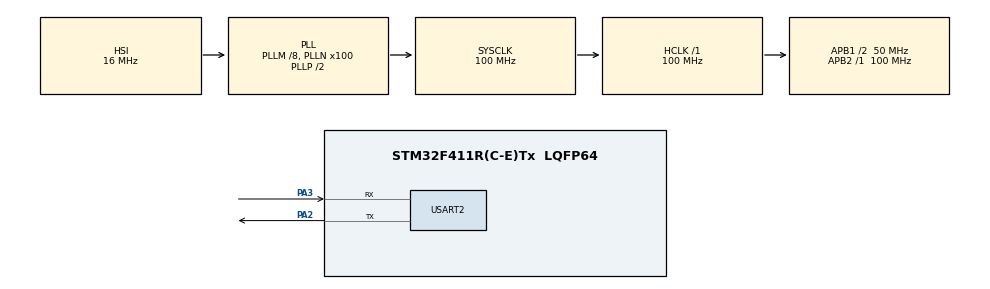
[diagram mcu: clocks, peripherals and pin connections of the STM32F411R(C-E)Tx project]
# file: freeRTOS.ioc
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FREERTOS.Tasks01=defaultTask,24,128,StartDefaultTask,Default,NULL,Dynamic,NULL,NULL;task1,8,128,funcTask1,Default,NULL,Dynamic,NULL,NULL;task2,8,128,funcTask2,Default,NULL,Dynamic,NULL,NULL
Mcu.Family=STM32F4
Mcu.Name=STM32F411R(C-E)Tx
Mcu.Package=LQFP64
NVIC.PriorityGroup=NVIC_PRIORITYGROUP_4
PA2.Mode=Asynchronous
PA2.Signal=USART2_TX
PA3.Mode=Asynchronous
PA3.Signal=USART2_RX
ProjectManager.HeapSize=0x200
ProjectManager.StackSize=0x400
ProjectManager.TargetToolchain=STM32CubeIDE
RCC.48MHZClocksFreq_Value=50000000
RCC.AHBFreq_Value=100000000
RCC.APB1CLKDivider=RCC_HCLK_DIV2
RCC.APB1Freq_Value=50000000
RCC.APB1TimFreq_Value=100000000
RCC.APB2Freq_Value=100000000
RCC.APB2TimFreq_Value=100000000
RCC.CortexFreq_Value=100000000
RCC.HCLKFreq_Value=100000000
RCC.HSE_VALUE=25000000
RCC.HSI_VALUE=16000000
RCC.LSE_VALUE=32768
RCC.PLLM=8
RCC.PLLN=100
RCC.SYSCLKFreq_VALUE=100000000
RCC.SYSCLKSource=RCC_SYSCLKSOURCE_PLLCLK
RCC.VCOOutputFreq_Value=200000000
USART2.VirtualMode=VM_ASYNC
VP_FREERTOS_VS_CMSIS_V2.Mode=CMSIS_V2
board=custom

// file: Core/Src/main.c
/* USER CODE BEGIN Header */
/**
  ******************************************************************************
  * @file           : main.c
  * @brief          : Main program body
  ******************************************************************************
  * @attention
  *
  * Copyright (c) 2024 STMicroelectronics.
  * All rights reserved.
  *
  * This software is licensed under terms that can be found in the LICENSE file
  * in the root directory of this software component.
  * If no LICENSE file comes with this software, it is provided AS-IS.
  *
  ******************************************************************************
  */
/* USER CODE END Header */
#include "main.h"
#include "cmsis_os.h"

UART_HandleTypeDef huart2;

/* Definitions for defaultTask */
osThreadId_t defaultTaskHandle;
const osThreadAttr_t defaultTask_attributes = {
  .name = "defaultTask",
  .stack_size = 128 * 4,
  .priority = (osPriority_t) osPriorityNormal,
};
/* Definitions for task1 */
osThreadId_t task1Handle;
const osThreadAttr_t task1_attributes = {
  .name = "task1",
  .stack_size = 128 * 4,
  .priority = (osPriority_t) osPriorityLow,
};
/* Definitions for task2 */
osThreadId_t task2Handle;
const osThreadAttr_t task2_attributes = {
  .name = "task2",
  .stack_size = 128 * 4,
  .priority = (osPriority_t) osPriorityLow,
};

void SystemClock_Config(void);
static void MX_GPIO_Init(void);
static void MX_USART2_UART_Init(void);
void StartDefaultTask(void *argument);
void funcTask1(void *argument);
void funcTask2(void *argument);

int main(void)
{

  /* MCU Configuration--------------------------------------------------------*/

  /* Reset of all peripherals, Initializes the Flash interface and the Systick. */
  HAL_Init();

  /* Configure the system clock */
  SystemClock_Config();

  /* Initialize all configured peripherals */
  MX_GPIO_Init();
  MX_USART2_UART_Init();

  /* Init scheduler */
  osKernelInitialize();

  /* Create the thread(s) */
  /* creation of defaultTask */
  defaultTaskHandle = osThreadNew(StartDefaultTask, NULL, &defaultTask_attributes);

  /* creation of task1 */
  task1Handle = osThreadNew(funcTask1, NULL, &task1_attributes);

  /* creation of task2 */
  task2Handle = osThreadNew(funcTask2, NULL, &task2_attributes);

  /* Start scheduler */
  osKernelStart();

  /* We should never get here as control is now taken by the scheduler */
  /* Infinite loop */
  while (1)
  {

  }
}

void SystemClock_Config(void)
{
  RCC_OscInitTypeDef RCC_OscInitStruct = {0};
  RCC_ClkInitTypeDef RCC_ClkInitStruct = {0};

  /** Configure the main internal regulator output voltage
  */
  __HAL_RCC_PWR_CLK_ENABLE();
  __HAL_PWR_VOLTAGESCALING_CONFIG(PWR_REGULATOR_VOLTAGE_SCALE1);

  /** Initializes the RCC Oscillators according to the specified parameters
  * in the RCC_OscInitTypeDef structure.
  */
  RCC_OscInitStruct.OscillatorType = RCC_OSCILLATORTYPE_HSI;
  RCC_OscInitStruct.HSIState = RCC_HSI_ON;
  RCC_OscInitStruct.HSICalibrationValue = RCC_HSICALIBRATION_DEFAULT;
  RCC_OscInitStruct.PLL.PLLState = RCC_PLL_ON;
  RCC_OscInitStruct.PLL.PLLSource = RCC_PLLSOURCE_HSI;
  RCC_OscInitStruct.PLL.PLLM = 8;
  RCC_OscInitStruct.PLL.PLLN = 100;
  RCC_OscInitStruct.PLL.PLLP = RCC_PLLP_DIV2;
  RCC_OscInitStruct.PLL.PLLQ = 4;
  if (HAL_RCC_OscConfig(&RCC_OscInitStruct) != HAL_OK)
  {
    Error_Handler();
  }

  /** Initializes the CPU, AHB and APB buses clocks
  */
  RCC_ClkInitStruct.ClockType = RCC_CLOCKTYPE_HCLK|RCC_CLOCKTYPE_SYSCLK
                              |RCC_CLOCKTYPE_PCLK1|RCC_CLOCKTYPE_PCLK2;
  RCC_ClkInitStruct.SYSCLKSource = RCC_SYSCLKSOURCE_PLLCLK;
  RCC_ClkInitStruct.AHBCLKDivider = RCC_SYSCLK_DIV1;
  RCC_ClkInitStruct.APB1CLKDivider = RCC_HCLK_DIV2;
  RCC_ClkInitStruct.APB2CLKDivider = RCC_HCLK_DIV1;

  if (HAL_RCC_ClockConfig(&RCC_ClkInitStruct, FLASH_LATENCY_3) != HAL_OK)
  {
    Error_Handler();
  }
}

static void MX_USART2_UART_Init(void)
{

  huart2.Instance = USART2;
  huart2.Init.BaudRate = 115200;
  huart2.Init.WordLength = UART_WORDLENGTH_8B;
  huart2.Init.StopBits = UART_STOPBITS_1;
  huart2.Init.Parity = UART_PARITY_NONE;
  huart2.Init.Mode = UART_MODE_TX_RX;
  huart2.Init.HwFlowCtl = UART_HWCONTROL_NONE;
  huart2.Init.OverSampling = UART_OVERSAMPLING_16;
  if (HAL_UART_Init(&huart2) != HAL_OK)
  {
    Error_Handler();
  }

}

static void MX_GPIO_Init(void)
{

  /* GPIO Ports Clock Enable */
  __HAL_RCC_GPIOA_CLK_ENABLE();

}

void StartDefaultTask(void *argument)
{
  /* USER CODE BEGIN 5 */
	initUart(&huart2);
  /* Infinite loop */
  for(;;)
  {
  	printf("default task\n");
    osDelay(50);
  }
  /* USER CODE END 5 */
}

void funcTask1(void *argument)
{
  /* USER CODE BEGIN funcTask1 */
  /* Infinite loop */
  for(;;)
  {
  	printf("funcTask1\n");
    osDelay(789);
  }
  /* USER CODE END funcTask1 */
}

void funcTask2(void *argument)
{
	printf("funcTast2\n");
	osDelay(1230);
  for(;;)
  {
    osDelay(1);
  }
}

void Error_Handler(void)
{
  __disable_irq();
  while (1)
  {
  }
}
